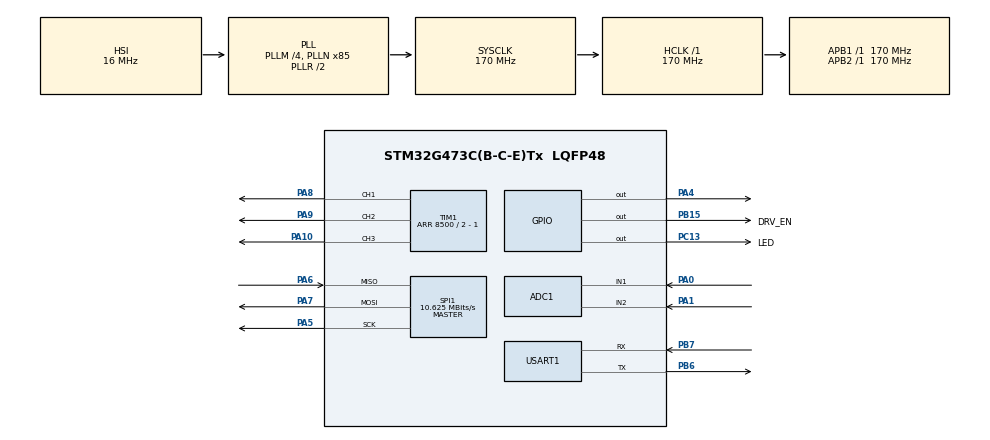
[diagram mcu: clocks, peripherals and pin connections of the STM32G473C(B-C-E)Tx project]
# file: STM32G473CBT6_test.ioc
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ADC1.Channel-0\#ChannelRegularConversion=ADC_CHANNEL_1
ADC1.Channel-1\#ChannelRegularConversion=ADC_CHANNEL_2
ADC1.ContinuousConvMode=ENABLE
ADC1.DMAContinuousRequests=ENABLE
ADC1.NbrOfConversion=2
ADC1.NbrOfConversionFlag=1
ADC1.OffsetNumber-0\#ChannelRegularConversion=ADC_OFFSET_NONE
ADC1.OffsetNumber-1\#ChannelRegularConversion=ADC_OFFSET_NONE
ADC1.Rank-0\#ChannelRegularConversion=1
ADC1.Rank-1\#ChannelRegularConversion=2
ADC1.SamplingTime-0\#ChannelRegularConversion=ADC_SAMPLETIME_2CYCLES_5
ADC1.SamplingTime-1\#ChannelRegularConversion=ADC_SAMPLETIME_2CYCLES_5
ADC1.master=1
Dma.ADC1.0.Direction=DMA_PERIPH_TO_MEMORY
Dma.ADC1.0.EventEnable=DISABLE
Dma.ADC1.0.Instance=DMA1_Channel1
Dma.ADC1.0.MemDataAlignment=DMA_MDATAALIGN_HALFWORD
Dma.ADC1.0.MemInc=DMA_MINC_ENABLE
Dma.ADC1.0.Mode=DMA_CIRCULAR
Dma.ADC1.0.PeriphDataAlignment=DMA_PDATAALIGN_HALFWORD
Dma.ADC1.0.PeriphInc=DMA_PINC_DISABLE
Dma.ADC1.0.Polarity=HAL_DMAMUX_REQ_GEN_RISING
Dma.ADC1.0.Priority=DMA_PRIORITY_LOW
Dma.ADC1.0.RequestNumber=1
Dma.ADC1.0.SignalID=NONE
Dma.ADC1.0.SyncEnable=DISABLE
Dma.ADC1.0.SyncPolarity=HAL_DMAMUX_SYNC_NO_EVENT
Dma.ADC1.0.SyncRequestNumber=1
Dma.ADC1.0.SyncSignalID=NONE
Dma.Request0=ADC1
Mcu.Family=STM32G4
Mcu.Name=STM32G473C(B-C-E)Tx
Mcu.Package=LQFP48
NVIC.PriorityGroup=NVIC_PRIORITYGROUP_4
PA0.Mode=IN1-Single-Ended
PA0.Signal=ADC1_IN1
PA1.Mode=IN2-Single-Ended
PA1.Signal=ADC1_IN2
PA10.Signal=S_TIM1_CH3
PA13.Mode=Serial_Wire
PA13.Signal=SYS_JTMS-SWDIO
PA14.Mode=Serial_Wire
PA14.Signal=SYS_JTCK-SWCLK
PA4.Signal=GPIO_Output
PA5.GPIO_Speed=GPIO_SPEED_FREQ_HIGH
PA5.Mode=Full_Duplex_Master
PA5.Signal=SPI1_SCK
PA6.GPIO_Speed=GPIO_SPEED_FREQ_HIGH
PA6.Mode=Full_Duplex_Master
PA6.Signal=SPI1_MISO
PA7.GPIO_Speed=GPIO_SPEED_FREQ_HIGH
PA7.Mode=Full_Duplex_Master
PA7.Signal=SPI1_MOSI
PA8.Signal=S_TIM1_CH1
PA9.Signal=S_TIM1_CH2
PB15.GPIO_Label=DRV_EN
PB15.Signal=GPIO_Output
PB6.Mode=Asynchronous
PB6.Signal=USART1_TX
PB7.Mode=Asynchronous
PB7.Signal=USART1_RX
PC13.GPIO_Label=LED
PC13.Signal=GPIO_Output
PF0-OSC_IN.Mode=HSE-External-Oscillator
PF0-OSC_IN.Signal=RCC_OSC_IN
PF1-OSC_OUT.Mode=HSE-External-Oscillator
PF1-OSC_OUT.Signal=RCC_OSC_OUT
ProjectManager.HeapSize=0x200
ProjectManager.StackSize=0x400
ProjectManager.TargetToolchain=MDK-ARM V5.32
RCC.ADC12Freq_Value=170000000
RCC.ADC345Freq_Value=170000000
RCC.AHBFreq_Value=170000000
RCC.APB1Freq_Value=170000000
RCC.APB1TimFreq_Value=170000000
RCC.APB2Freq_Value=170000000
RCC.APB2TimFreq_Value=170000000
RCC.CortexFreq_Value=170000000
RCC.EXTERNAL_CLOCK_VALUE=12288000
RCC.HCLKFreq_Value=170000000
RCC.HSE_VALUE=8000000
RCC.HSI48_VALUE=48000000
RCC.HSI_VALUE=16000000
RCC.LSE_VALUE=32768
RCC.PLLM=RCC_PLLM_DIV4
RCC.PLLN=85
RCC.SYSCLKFreq_VALUE=170000000
RCC.SYSCLKSource=RCC_SYSCLKSOURCE_PLLCLK
RCC.USBFreq_Value=170000000
RCC.VCOOutputFreq_Value=340000000
SH.S_TIM1_CH1.0=TIM1_CH1,PWM Generation1 CH1
SH.S_TIM1_CH2.0=TIM1_CH2,PWM Generation2 CH2
SH.S_TIM1_CH3.0=TIM1_CH3,PWM Generation3 CH3
SPI1.BaudRatePrescaler=SPI_BAUDRATEPRESCALER_16
SPI1.CLKPhase=SPI_PHASE_2EDGE
SPI1.CalculateBaudRate=10.625 MBits/s
SPI1.DataSize=SPI_DATASIZE_16BIT
SPI1.Direction=SPI_DIRECTION_2LINES
SPI1.Mode=SPI_MODE_MASTER
SPI1.VirtualType=VM_MASTER
TIM1.Channel-PWM\ Generation1\ CH1=TIM_CHANNEL_1
TIM1.Channel-PWM\ Generation2\ CH2=TIM_CHANNEL_2
TIM1.Channel-PWM\ Generation3\ CH3=TIM_CHANNEL_3
TIM1.Channel-PWM\ Generation4\ No\ Output=TIM_CHANNEL_4
TIM1.CounterMode=TIM_COUNTERMODE_CENTERALIGNED1
TIM1.PeriodNoDither=8500 / 2 - 1
USART1.VirtualMode-Asynchronous=VM_ASYNC
VP_SYS_VS_DBSignals.Mode=DisableDeadBatterySignals
VP_TIM1_VS_ClockSourceINT.Mode=Internal
VP_TIM1_VS_no_output4.Mode=PWM Generation4 No Output
VP_TIM6_VS_ClockSourceINT.Mode=Enable_Timer
VP_TIM7_VS_ClockSourceINT.Mode=Enable_Timer
board=custom

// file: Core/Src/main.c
/* USER CODE BEGIN Header */
/**
  ******************************************************************************
  * @file           : main.c
  * @brief          : Main program body
  ******************************************************************************
  * @attention
  *
  * Copyright (c) 2026 STMicroelectronics.
  * All rights reserved.
  *
  * This software is licensed under terms that can be found in the LICENSE file
  * in the root directory of this software component.
  * If no LICENSE file comes with this software, it is provided AS-IS.
  *
  ******************************************************************************
  */
/* USER CODE END Header */
#include "main.h"
#include "adc.h"
#include "dma.h"
#include "spi.h"
#include "tim.h"
#include "usart.h"
#include "gpio.h"

/* USER CODE BEGIN Includes */
#include "app_main.h"
/* USER CODE END Includes */

void SystemClock_Config(void);

int main(void)
{

  /* MCU Configuration--------------------------------------------------------*/

  /* Reset of all peripherals, Initializes the Flash interface and the Systick. */
  HAL_Init();

  /* Configure the system clock */
  SystemClock_Config();

  /* Initialize all configured peripherals */
  MX_GPIO_Init();
  MX_DMA_Init();
  MX_ADC1_Init();
  MX_SPI1_Init();
  MX_TIM1_Init();
  MX_TIM6_Init();
  MX_TIM7_Init();
  MX_USART1_UART_Init();
  /* USER CODE BEGIN 2 */
  App_Init();
  App_Start();
  /* USER CODE END 2 */

  /* Infinite loop */
  /* USER CODE BEGIN WHILE */
  while (1)
  {
    App_Loop();
    /* USER CODE END WHILE */

  }
}

void SystemClock_Config(void)
{
  RCC_OscInitTypeDef RCC_OscInitStruct = {0};
  RCC_ClkInitTypeDef RCC_ClkInitStruct = {0};

  /** Configure the main internal regulator output voltage
  */
  HAL_PWREx_ControlVoltageScaling(PWR_REGULATOR_VOLTAGE_SCALE1_BOOST);

  /** Initializes the RCC Oscillators according to the specified parameters
  * in the RCC_OscInitTypeDef structure.
  */
  RCC_OscInitStruct.OscillatorType = RCC_OSCILLATORTYPE_HSI;
  RCC_OscInitStruct.HSIState = RCC_HSI_ON;
  RCC_OscInitStruct.HSICalibrationValue = RCC_HSICALIBRATION_DEFAULT;
  RCC_OscInitStruct.PLL.PLLState = RCC_PLL_ON;
  RCC_OscInitStruct.PLL.PLLSource = RCC_PLLSOURCE_HSI;
  RCC_OscInitStruct.PLL.PLLM = RCC_PLLM_DIV4;
  RCC_OscInitStruct.PLL.PLLN = 85;
  RCC_OscInitStruct.PLL.PLLP = RCC_PLLP_DIV2;
  RCC_OscInitStruct.PLL.PLLQ = RCC_PLLQ_DIV2;
  RCC_OscInitStruct.PLL.PLLR = RCC_PLLR_DIV2;
  if (HAL_RCC_OscConfig(&RCC_OscInitStruct) != HAL_OK)
  {
    Error_Handler();
  }

  /** Initializes the CPU, AHB and APB buses clocks
  */
  RCC_ClkInitStruct.ClockType = RCC_CLOCKTYPE_HCLK|RCC_CLOCKTYPE_SYSCLK
                              |RCC_CLOCKTYPE_PCLK1|RCC_CLOCKTYPE_PCLK2;
  RCC_ClkInitStruct.SYSCLKSource = RCC_SYSCLKSOURCE_PLLCLK;
  RCC_ClkInitStruct.AHBCLKDivider = RCC_SYSCLK_DIV1;
  RCC_ClkInitStruct.APB1CLKDivider = RCC_HCLK_DIV1;
  RCC_ClkInitStruct.APB2CLKDivider = RCC_HCLK_DIV1;

  if (HAL_RCC_ClockConfig(&RCC_ClkInitStruct, FLASH_LATENCY_4) != HAL_OK)
  {
    Error_Handler();
  }
}

void Error_Handler(void)
{
  __disable_irq();
  while (1)
  {
  }
}
